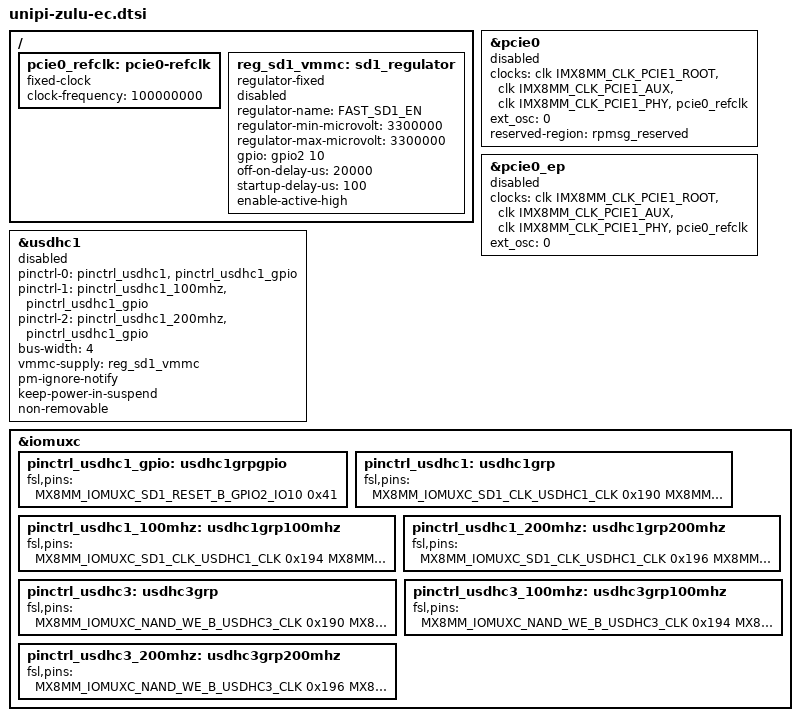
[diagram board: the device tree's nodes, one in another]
// SPDX-License-Identifier: (GPL-2.0+ OR MIT)
/*
 * Copyright 2020 Faster CZ
 * Copyright 2019 NXP
 */

/dts-v1/;

#include <dt-bindings/usb/pd.h>
#include "unipi-zulu.dtsi"

/ {
	/* Unipi Zulu with extendede connector */

	pcie0_refclk: pcie0-refclk {
		compatible = "fixed-clock";
		#clock-cells = <0>;
		clock-frequency = <100000000>;
	};

	reg_sd1_vmmc: sd1_regulator {
		compatible = "regulator-fixed";
		regulator-name = "FAST_SD1_EN";
		regulator-min-microvolt = <3300000>;
		regulator-max-microvolt = <3300000>;
		gpio = <&gpio2 10 GPIO_ACTIVE_HIGH>;
		off-on-delay-us = <20000>;
		startup-delay-us = <100>;
		enable-active-high;
		status = "disabled";
	};
};

&pcie0{
	// Pouzit jako reset treba strobe z SD1
	//pinctrl-names = "default";
	//pinctrl-0 = <&pinctrl_pcie0>;
	//disable-gpio = <&gpio1 5 GPIO_ACTIVE_LOW>;
	//reset-gpio = <&gpio4 21 GPIO_ACTIVE_LOW>;
	clocks = <&clk IMX8MM_CLK_PCIE1_ROOT>,
		 <&clk IMX8MM_CLK_PCIE1_AUX>,
		 <&clk IMX8MM_CLK_PCIE1_PHY>,
		 <&pcie0_refclk>;
	clock-names = "pcie", "pcie_aux", "pcie_phy", "pcie_bus";
	ext_osc = <0>;
	reserved-region = <&rpmsg_reserved>;
	status = "disabled";
};

&pcie0_ep{
	clocks = <&clk IMX8MM_CLK_PCIE1_ROOT>,
		 <&clk IMX8MM_CLK_PCIE1_AUX>,
		 <&clk IMX8MM_CLK_PCIE1_PHY>,
		 <&pcie0_refclk>;
	clock-names = "pcie", "pcie_aux", "pcie_phy", "pcie_bus";
	ext_osc = <0>;
	status = "disabled";
};



&usdhc1 {
	/* on fast connector */
	pinctrl-names = "default", "state_100mhz", "state_200mhz";
	pinctrl-0 = <&pinctrl_usdhc1>, <&pinctrl_usdhc1_gpio>;
	pinctrl-1 = <&pinctrl_usdhc1_100mhz>, <&pinctrl_usdhc1_gpio>;
	pinctrl-2 = <&pinctrl_usdhc1_200mhz>, <&pinctrl_usdhc1_gpio>;
	bus-width = <4>;
	vmmc-supply = <&reg_sd1_vmmc>;
	pm-ignore-notify;
	keep-power-in-suspend;
	non-removable;
	status = "disabled";
};


&iomuxc {

	pinctrl_usdhc1_gpio: usdhc1grpgpio {
		/* OK on fast connector */
		fsl,pins = <MX8MM_IOMUXC_SD1_RESET_B_GPIO2_IO10	0x41>;
	};

	pinctrl_usdhc1: usdhc1grp {
		/* OK on fast connector */
		fsl,pins = <
			MX8MM_IOMUXC_SD1_CLK_USDHC1_CLK			0x190
			MX8MM_IOMUXC_SD1_CMD_USDHC1_CMD			0x1d0
			MX8MM_IOMUXC_SD1_DATA0_USDHC1_DATA0		0x1d0
			MX8MM_IOMUXC_SD1_DATA1_USDHC1_DATA1		0x1d0
			MX8MM_IOMUXC_SD1_DATA2_USDHC1_DATA2		0x1d0
			MX8MM_IOMUXC_SD1_DATA3_USDHC1_DATA3		0x1d0
			MX8MM_IOMUXC_SD1_STROBE_USDHC1_STROBE	0x1d0
		>;
	};

	pinctrl_usdhc1_100mhz: usdhc1grp100mhz {
		fsl,pins = <
			MX8MM_IOMUXC_SD1_CLK_USDHC1_CLK			0x194
			MX8MM_IOMUXC_SD1_CMD_USDHC1_CMD			0x1d4
			MX8MM_IOMUXC_SD1_DATA0_USDHC1_DATA0		0x1d4
			MX8MM_IOMUXC_SD1_DATA1_USDHC1_DATA1		0x1d4
			MX8MM_IOMUXC_SD1_DATA2_USDHC1_DATA2		0x1d4
			MX8MM_IOMUXC_SD1_DATA3_USDHC1_DATA3		0x1d4
		>;
	};

	pinctrl_usdhc1_200mhz: usdhc1grp200mhz {
		fsl,pins = <
			MX8MM_IOMUXC_SD1_CLK_USDHC1_CLK			0x196
			MX8MM_IOMUXC_SD1_CMD_USDHC1_CMD			0x1d6
			MX8MM_IOMUXC_SD1_DATA0_USDHC1_DATA0		0x1d6
			MX8MM_IOMUXC_SD1_DATA1_USDHC1_DATA1		0x1d6
			MX8MM_IOMUXC_SD1_DATA2_USDHC1_DATA2		0x1d6
			MX8MM_IOMUXC_SD1_DATA3_USDHC1_DATA3		0x1d6
		>;
	};

	pinctrl_usdhc3: usdhc3grp {
		fsl,pins = <
			MX8MM_IOMUXC_NAND_WE_B_USDHC3_CLK			0x190
			MX8MM_IOMUXC_NAND_WP_B_USDHC3_CMD			0x1d0
			MX8MM_IOMUXC_NAND_DATA04_USDHC3_DATA0		0x1d0
			MX8MM_IOMUXC_NAND_DATA05_USDHC3_DATA1		0x1d0
			MX8MM_IOMUXC_NAND_DATA06_USDHC3_DATA2		0x1d0
			MX8MM_IOMUXC_NAND_DATA07_USDHC3_DATA3		0x1d0
			MX8MM_IOMUXC_NAND_RE_B_USDHC3_DATA4			0x1d0
			MX8MM_IOMUXC_NAND_CE2_B_USDHC3_DATA5		0x1d0
			MX8MM_IOMUXC_NAND_CE3_B_USDHC3_DATA6		0x1d0
			MX8MM_IOMUXC_NAND_CLE_USDHC3_DATA7			0x1d0
			MX8MM_IOMUXC_NAND_CE1_B_USDHC3_STROBE 		0x190
		>;
	};

	pinctrl_usdhc3_100mhz: usdhc3grp100mhz {
		fsl,pins = <
			MX8MM_IOMUXC_NAND_WE_B_USDHC3_CLK			0x194
			MX8MM_IOMUXC_NAND_WP_B_USDHC3_CMD			0x1d4
			MX8MM_IOMUXC_NAND_DATA04_USDHC3_DATA0		0x1d4
			MX8MM_IOMUXC_NAND_DATA05_USDHC3_DATA1		0x1d4
			MX8MM_IOMUXC_NAND_DATA06_USDHC3_DATA2		0x1d4
			MX8MM_IOMUXC_NAND_DATA07_USDHC3_DATA3		0x1d4
			MX8MM_IOMUXC_NAND_RE_B_USDHC3_DATA4			0x1d4
			MX8MM_IOMUXC_NAND_CE2_B_USDHC3_DATA5		0x1d4
			MX8MM_IOMUXC_NAND_CE3_B_USDHC3_DATA6		0x1d4
			MX8MM_IOMUXC_NAND_CLE_USDHC3_DATA7			0x1d4
			MX8MM_IOMUXC_NAND_CE1_B_USDHC3_STROBE 		0x194
		>;
	};

	pinctrl_usdhc3_200mhz: usdhc3grp200mhz {
		fsl,pins = <
			MX8MM_IOMUXC_NAND_WE_B_USDHC3_CLK			0x196
			MX8MM_IOMUXC_NAND_WP_B_USDHC3_CMD			0x1d6
			MX8MM_IOMUXC_NAND_DATA04_USDHC3_DATA0		0x1d6
			MX8MM_IOMUXC_NAND_DATA05_USDHC3_DATA1		0x1d6
			MX8MM_IOMUXC_NAND_DATA06_USDHC3_DATA2		0x1d6
			MX8MM_IOMUXC_NAND_DATA07_USDHC3_DATA3		0x1d6
			MX8MM_IOMUXC_NAND_RE_B_USDHC3_DATA4			0x1d6
			MX8MM_IOMUXC_NAND_CE2_B_USDHC3_DATA5		0x1d6
			MX8MM_IOMUXC_NAND_CE3_B_USDHC3_DATA6		0x1d6
			MX8MM_IOMUXC_NAND_CLE_USDHC3_DATA7			0x1d6
			MX8MM_IOMUXC_NAND_CE1_B_USDHC3_STROBE 		0x196
		>;
	};
};
